# AT32UC3A3128 device description
Architecture: AVR32_UC3; Family: AVR UC3
Registers are 32-bit, read-write, reset 0x0 unless marked. A register's access mark holds for its fields unless they carry their own. Offsets are from the block's base; [hi:lo] are bit positions; {n}, {i} and the like mark numbered series.

## INTC — Interrupt Controller
Instances: INTC 0xFFFF0800
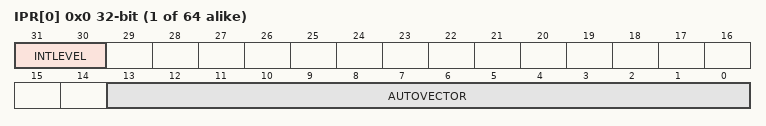
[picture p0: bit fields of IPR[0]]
{0x0+4i} IPR[{i}] (i=0..63) — Interrupt Priority Register
  [31:30] INTLEVEL — Interrupt Level
    {v}=INT{v} (v=0..3)
  [13:0] AUTOVECTOR — Handler offset
{0x100+4i} IRR[{i}] (i=0..63) ro — Interrupt Request Register
{0x200+4i} ICR[{i}] (i=0..3) ro — Interrupt Cause Register
  [5:0] CAUSE — Cause Group Number

## ADC — Analog to Digital Converter
Instances: ADC 0xffff3c00
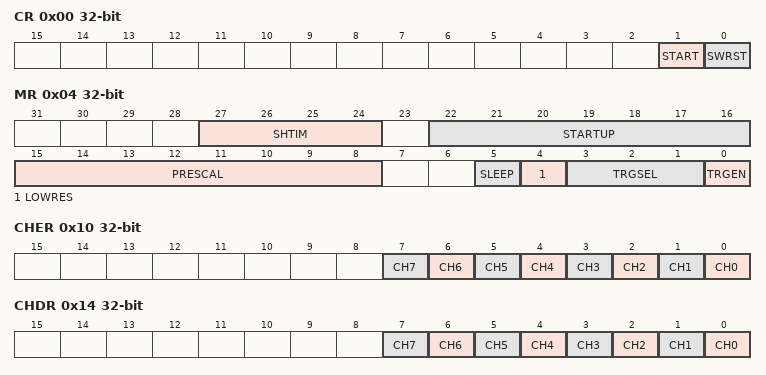
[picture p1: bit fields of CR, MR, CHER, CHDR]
0x00 CR wo reset not defined — Control Register
  [1] START — Start Conversion
  [0] SWRST — Software Reset
0x04 MR — Mode Register
  [27:24] SHTIM — Sample and Hold Time
  [22:16] STARTUP — Start Up Time
  [15:8] PRESCAL — Prescaler Rate Selection
  [5] SLEEP — Sleep Mode
  [4] LOWRES — Resolution
  [3:1] TRGSEL — Trigger Selection
  [0] TRGEN — Trigger Enable
0x10 CHER wo reset not defined — Channel Enable Register
  [n] CH{n} (n=0..7) — Channel {n} Enable
0x14 CHDR wo reset not defined — Channel Disable Register
  [n] CH{n} (n=0..7) — Channel {n} Disable
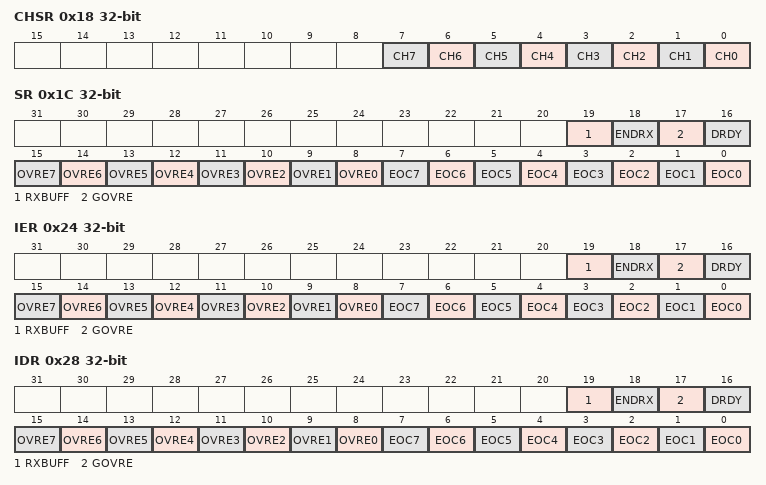
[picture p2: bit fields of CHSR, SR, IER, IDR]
0x18 CHSR ro — Channel Status Register
  [n] CH{n} (n=0..7)
0x1C SR ro reset not defined — Status Register
  [19] RXBUFF — RX Buffer Full
  [18] ENDRX — End of RX Buffer
  [17] GOVRE — General Overrun Error
  [16] DRDY — Data Ready
  [n+8] OVRE{n} (n=0..7) — Overrun Error {n}
  [n] EOC{n} (n=0..7) — End of Conversion {n}
0x20 LCDR ro reset not defined — Last Converted Data Register
  [9:0] LDATA — Last Data Converted
0x24 IER wo reset not defined — Interrupt Enable Register
  [19] RXBUFF — Receive Buffer Full Interrupt Enable
  [18] ENDRX — End of Receive Buffer Interrupt Enable
  [17] GOVRE — General Overrun Error Interrupt Enable
  [16] DRDY — Data Ready Interrupt Enable
  [n+8] OVRE{n} (n=0..7) — Overrun Error Interrupt Enable {n}
  [n] EOC{n} (n=0..7) — End of Conversion Interrupt Enable {n}
0x28 IDR wo reset not defined — Interrupt Disable Register
  [19] RXBUFF — Receive Buffer Full Interrupt Disable
  [18] ENDRX — End of Receive Buffer Interrupt Disable
  [17] GOVRE — General Overrun Interrupt Disable
  [16] DRDY — Data Ready Interrupt Disable
  [n+8] OVRE{n} (n=0..7) — Overrun Error Interrupt Disable {n}
  [n] EOC{n} (n=0..7) — End of Conversion Interrupt Disable {n}
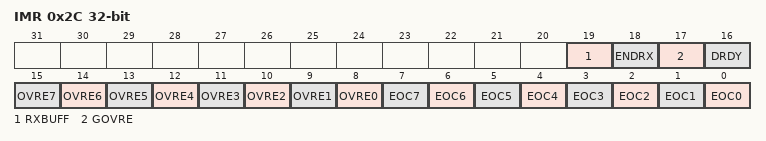
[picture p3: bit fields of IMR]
0x2C IMR ro — Interrupt Mask Register
  [19] RXBUFF — Receive Buffer Full Interrupt Mask
  [18] ENDRX — End of Receive Buffer Interrupt Mask
  [17] GOVRE — General Overrun Error Interrupt Mask
  [16] DRDY — Data Ready Interrupt Mask
  [n+8] OVRE{n} (n=0..7) — Overrun Error Interrupt Mask {n}
  [n] EOC{n} (n=0..7) — End of Conversion Interrupt Mask {n}
{0x30+4i} CDR{i} ro (i=0..7) — Channel Data Register {i}
  [9:0] DATA — Converted Data
0xFC VERSION ro reset not defined

## BUSMON — Bus Monitor module
Instances: BUSMON 0xfffe2800
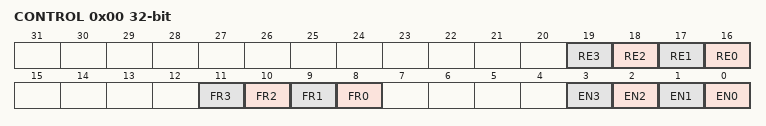
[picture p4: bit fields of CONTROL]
0x00 CONTROL
  [n+16] RE{n} (n=0..3), [n+8] FR{n} (n=0..3), [n] EN{n} (n=0..3)
{0x10+0x10*i} DATA{i} ro (i=0..3) — Data Cycles Channel {i}
{0x14+0x10*i} STALL{i} ro (i=0..3) — Stall Cycles Channel {i}
{0x18+0x10*i} LAT{i} ro (i=0..3) — Max Latency Cycles Channel {i}

## ABDAC — Audio Bitstream DAC
Instances: ABDAC 0xffff4000
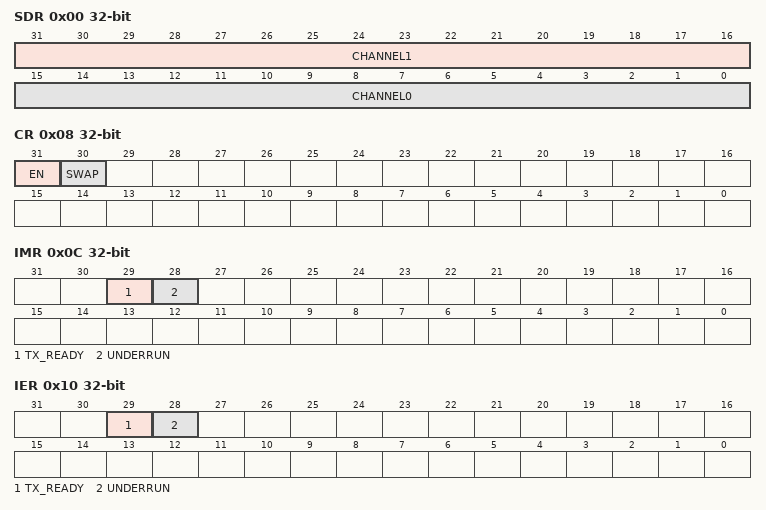
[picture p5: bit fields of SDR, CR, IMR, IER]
0x00 SDR — Sample Data Register
  [31:16] CHANNEL1 — Sample Data for Channel 1
  [15:0] CHANNEL0 — Sample Data for Channel 0
0x08 CR reset not defined — Control Register
  [31] EN — Enable Audio DAC.
  [30] SWAP — Swap Channels
0x0C IMR ro reset not defined — Interrupt Mask Register
  [29] TX_READY — TX Ready Interrupt Mask
  [28] UNDERRUN — Underrun Interrupt Mask
0x10 IER wo reset not defined — Interrupt Enable Register
  [29] TX_READY — TX Ready Interrupt Enable
  [28] UNDERRUN — Underrun Interrupt Enable
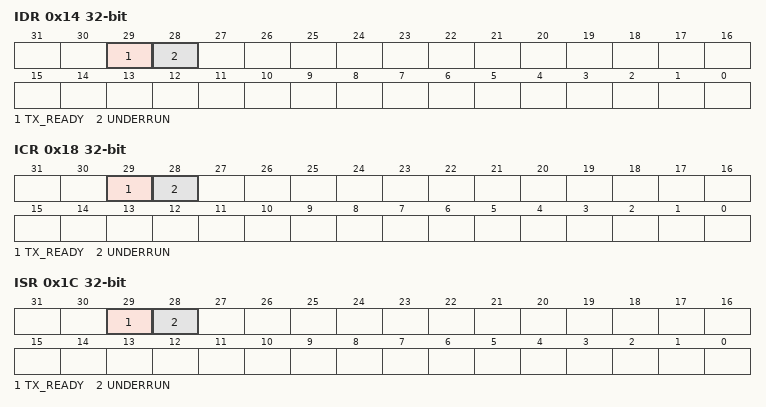
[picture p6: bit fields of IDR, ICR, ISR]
0x14 IDR wo reset not defined — Interupt Disable Register
  [29] TX_READY — TX Ready Interrupt Disable
  [28] UNDERRUN — Underrun Interrupt Disable
0x18 ICR wo reset not defined — Interrupt Clear Register
  [29] TX_READY — TX Ready Interrupt Clear
  [28] UNDERRUN — Underrun Interrupt Clear
0x1C ISR ro reset not defined — Interrupt Status Register
  [29] TX_READY — Interrupt Status Register
  [28] UNDERRUN — Interrupt Status Register
